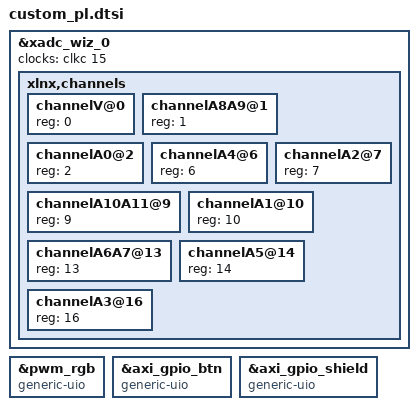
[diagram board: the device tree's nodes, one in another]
&xadc_wiz_0 {
	clocks = <&clkc 15>;
	xlnx,channels {
		#address-cells = <1>;
		#size-cells = <0>;
		channelV@0 { /* V_P/V_N */
			reg = <0>;
		};
		channelA8A9@1 { /* vaux0 */
			reg = <1>;
		};
		channelA0@2 {
			reg = <2>;
		};
		channelA4@6 {
			reg = <6>;
		};
		channelA2@7 {
			reg = <7>;
		};
		channelA10A11@9 {
			reg = <9>;
		};
		channelA1@10 {
			reg = <10>;
		};
		channelA6A7@13 {
			reg = <13>;
		};
		channelA5@14 {
			reg = <14>;
		};
		channelA3@16 {
			reg = <16>;
		};
	};
};


&pwm_rgb {
	compatible = "generic-uio";	
};

&axi_gpio_btn {
	compatible = "generic-uio";
};
&axi_gpio_shield {
	compatible = "generic-uio";
};
